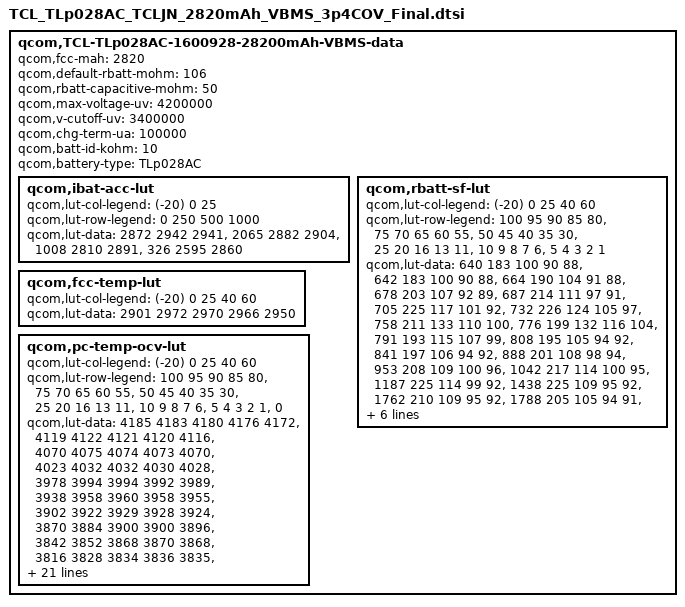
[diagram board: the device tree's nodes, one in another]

 qcom,TCL-TLp028AC-1600928-28200mAh-VBMS-data {
	qcom,fcc-mah = <2820>;
	qcom,default-rbatt-mohm = <106>;
	qcom,rbatt-capacitive-mohm = <50>;
	qcom,max-voltage-uv = <4200000>;
	qcom,v-cutoff-uv = <3400000>;
	qcom,chg-term-ua = <100000>;
	qcom,batt-id-kohm = <10>;
    qcom,battery-type = "TLp028AC";

	qcom,ibat-acc-lut {
		qcom,lut-col-legend = <(-20) 0 25>;
		qcom,lut-row-legend = <0 250 500 1000>;
		qcom,lut-data = <2872 2942 2941>,
				<2065 2882 2904>,
				<1008 2810 2891>,
				<326 2595 2860>;
	};

	qcom,rbatt-sf-lut {
		qcom,lut-col-legend = <(-20) 0 25 40 60>;
		qcom,lut-row-legend = <100 95 90 85 80>,
				<75 70 65 60 55>,
				<50 45 40 35 30>,
				<25 20 16 13 11>,
				<10 9 8 7 6>,
				<5 4 3 2 1>;
		qcom,lut-data = <640 183 100 90 88>,
				<642 183 100 90 88>,
				<664 190 104 91 88>,
				<678 203 107 92 89>,
				<687 214 111 97 91>,
				<705 225 117 101 92>,
				<732 226 124 105 97>,
				<758 211 133 110 100>,
				<776 199 132 116 104>,
				<791 193 115 107 99>,
				<808 195 105 94 92>,
				<841 197 106 94 92>,
				<888 201 108 98 94>,
				<953 208 109 100 96>,
				<1042 217 114 100 95>,
				<1187 225 114 99 92>,
				<1438 225 109 95 92>,
				<1762 210 109 95 92>,
				<1788 205 105 94 91>,
				<1871 209 104 93 91>,
				<2064 216 105 94 92>,
				<2308 225 108 96 93>,
				<2588 238 111 100 94>,
				<2935 258 115 101 95>,
				<3346 279 120 103 95>,
				<3827 302 121 102 95>,
				<4398 327 116 99 93>,
				<5099 366 117 99 94>,
				<5883 445 120 102 95>,
				<6896 579 127 108 101>;
	};

	qcom,fcc-temp-lut {
		qcom,lut-col-legend = <(-20) 0 25 40 60>;
		qcom,lut-data = <2901 2972 2970 2966 2950>;
	};

	qcom,pc-temp-ocv-lut {
		qcom,lut-col-legend = <(-20) 0 25 40 60>;
		qcom,lut-row-legend = <100 95 90 85 80>,
				<75 70 65 60 55>,
				<50 45 40 35 30>,
				<25 20 16 13 11>,
				<10 9 8 7 6>,
				<5 4 3 2 1>,
				<0>;
		qcom,lut-data = <4185 4183 4180 4176 4172>,
				<4119 4122 4121 4120 4116>,
				<4070 4075 4074 4073 4070>,
				<4023 4032 4032 4030 4028>,
				<3978 3994 3994 3992 3989>,
				<3938 3958 3960 3958 3955>,
				<3902 3922 3929 3928 3924>,
				<3870 3884 3900 3900 3896>,
				<3842 3852 3868 3870 3868>,
				<3816 3828 3834 3836 3835>,
				<3795 3808 3808 3808 3807>,
				<3779 3792 3792 3792 3790>,
				<3766 3780 3780 3779 3777>,
				<3754 3770 3770 3768 3766>,
				<3742 3763 3762 3758 3752>,
				<3728 3752 3752 3744 3732>,
				<3711 3731 3732 3722 3710>,
				<3694 3704 3706 3698 3686>,
				<3678 3688 3679 3672 3660>,
				<3666 3680 3670 3662 3652>,
				<3657 3676 3668 3660 3650>,
				<3648 3673 3665 3658 3648>,
				<3636 3670 3662 3656 3646>,
				<3623 3664 3659 3652 3642>,
				<3606 3658 3654 3648 3637>,
				<3583 3643 3644 3637 3624>,
				<3555 3614 3616 3608 3594>,
				<3520 3570 3570 3560 3548>,
				<3474 3510 3510 3500 3489>,
				<3404 3426 3423 3418 3410>,
				<3300 3300 3300 3300 3300>;
	};
};
